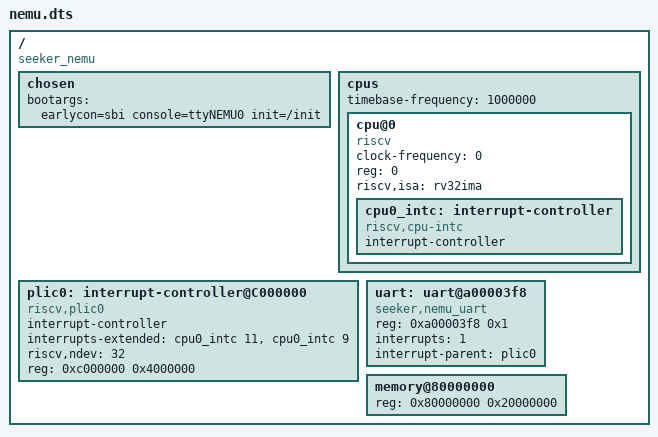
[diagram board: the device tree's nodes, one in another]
/dts-v1/;

/ {
	#address-cells = <1>;
	#size-cells = <1>;

	compatible = "seeker_nemu";
	chosen {
		bootargs = "earlycon=sbi console=ttyNEMU0 init=/init";
	};

	cpus {
		#address-cells = <1>;
		#size-cells = <0>;
		timebase-frequency = <1000000>;
		cpu@0 {
			clock-frequency = <0>;
			compatible = "riscv";
			device_type = "cpu";
			status = "okay";
			reg = <0>;
			riscv,isa = "rv32ima";
			cpu0_intc: interrupt-controller {
				#interrupt-cells = <1>;
				compatible = "riscv,cpu-intc";
				interrupt-controller;
			};
		};
	};

	plic0: interrupt-controller@C000000 {
		#address-cells = <0>;
		#interrupt-cells = <1>;
		compatible = "riscv,plic0";
		interrupt-controller;
		interrupts-extended =
			<&cpu0_intc 11 &cpu0_intc 9>;
		riscv,ndev = <32>;  // 支持的最大设备中断号+1（至少覆盖你的UART中断号）

		reg = <0xc000000 0x4000000>;
	};

	uart: uart@a00003f8 {
		compatible = "seeker,nemu_uart";
		reg = <0xa00003f8 0x1>;
		interrupts = <1>;         // 使用PLIC中断源1（可自定义，但需<=riscv,ndev-1）
		interrupt-parent = <&plic0>;  // 关联到PLIC
		status = "okay";
	};

	memory@80000000 {
		device_type = "memory";
		reg = <0x80000000 0x20000000>;
	};

};
